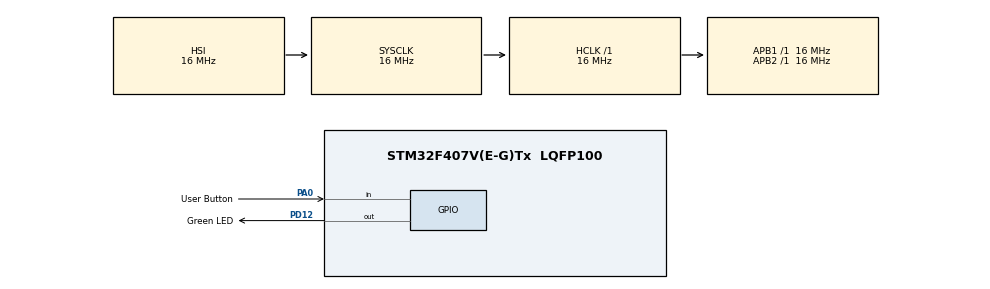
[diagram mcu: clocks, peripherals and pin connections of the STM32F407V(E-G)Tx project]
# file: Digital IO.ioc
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Mcu.Family=STM32F4
Mcu.Name=STM32F407V(E-G)Tx
Mcu.Package=LQFP100
NVIC.PriorityGroup=NVIC_PRIORITYGROUP_4
PA0-WKUP.GPIO_Label=User Button
PA0-WKUP.Signal=GPIO_Input
PA13.Mode=Trace_Asynchronous_SW
PA13.Signal=SYS_JTMS-SWDIO
PA14.Mode=Trace_Asynchronous_SW
PA14.Signal=SYS_JTCK-SWCLK
PB3.Mode=Trace_Asynchronous_SW
PB3.Signal=SYS_JTDO-SWO
PD12.GPIO_Label=Green LED
PD12.PinState=GPIO_PIN_RESET
PD12.Signal=GPIO_Output
ProjectManager.HeapSize=0x200
ProjectManager.StackSize=0x400
ProjectManager.TargetToolchain=STM32CubeIDE
RCC.AHBFreq_Value=16000000
RCC.APB1Freq_Value=16000000
RCC.APB2Freq_Value=16000000
RCC.CortexFreq_Value=16000000
RCC.HSE_VALUE=25000000
RCC.HSI_VALUE=16000000
RCC.LSE_VALUE=32768
RCC.SYSCLKFreq_VALUE=16000000
RCC.VCOOutputFreq_Value=192000000
board=custom

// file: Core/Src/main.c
/* USER CODE BEGIN Header */
/**
  ******************************************************************************
  * @file           : main.c
  * @brief          : Main program body
  ******************************************************************************
  * @attention
  *
  * Copyright (c) 2023 STMicroelectronics.
  * All rights reserved.
  *
  * This software is licensed under terms that can be found in the LICENSE file
  * in the root directory of this software component.
  * If no LICENSE file comes with this software, it is provided AS-IS.
  *
  ******************************************************************************
  */
/* USER CODE END Header */
#include "main.h"

/* USER CODE BEGIN Includes */
#include "stdio.h"

/* USER CODE END Includes */

void SystemClock_Config(void);
static void MX_GPIO_Init(void);
void blink(GPIO_PIN_Letter, GPIO_PIN_Number);
/* USER CODE BEGIN PFP */

// https://www.youtube.com/watch?v=FDCI4yfovfw
// ^ For printing using semihosting

// Docmentation at
// https://community.st.com/t5/stm32-mcus/how-to-use-semihosting-with-stm32cubeide-and-stm32/ta-p/49742

extern void initialise_monitor_handles(void);
/* USER CODE END PFP */

int main(void)
{
  /* USER CODE BEGIN 1 */
int bool = 0;
  /* USER CODE END 1 */

  /* MCU Configuration--------------------------------------------------------*/

  /* Reset of all peripherals, Initializes the Flash interface and the Systick. */
  HAL_Init();

  /* USER CODE BEGIN Init */
  initialise_monitor_handles();
  /* USER CODE END Init */

  /* Configure the system clock */
  SystemClock_Config();

  /* Initialize all configured peripherals */
  MX_GPIO_Init();
  /* USER CODE BEGIN 2 */
  printf("Hello World!\n");
  /* USER CODE END 2 */

  /* Infinite loop */
  /* USER CODE BEGIN WHILE */
  while (1)
  {
	  if(HAL_GPIO_ReadPin(GPIOA, GPIO_PIN_0))
		  bool = 1;

	  if((!HAL_GPIO_ReadPin(GPIOA, GPIO_PIN_0)) && bool){
		  blink(GPIOD, GPIO_PIN_12);
		  bool = 0;
		  printf("Hello World!\n");
	  }

    /* USER CODE END WHILE */

  }
}

void SystemClock_Config(void)
{
  RCC_OscInitTypeDef RCC_OscInitStruct = {0};
  RCC_ClkInitTypeDef RCC_ClkInitStruct = {0};

  /** Configure the main internal regulator output voltage
  */
  __HAL_RCC_PWR_CLK_ENABLE();
  __HAL_PWR_VOLTAGESCALING_CONFIG(PWR_REGULATOR_VOLTAGE_SCALE1);

  /** Initializes the RCC Oscillators according to the specified parameters
  * in the RCC_OscInitTypeDef structure.
  */
  RCC_OscInitStruct.OscillatorType = RCC_OSCILLATORTYPE_HSI;
  RCC_OscInitStruct.HSIState = RCC_HSI_ON;
  RCC_OscInitStruct.HSICalibrationValue = RCC_HSICALIBRATION_DEFAULT;
  RCC_OscInitStruct.PLL.PLLState = RCC_PLL_NONE;
  if (HAL_RCC_OscConfig(&RCC_OscInitStruct) != HAL_OK)
  {
    Error_Handler();
  }

  /** Initializes the CPU, AHB and APB buses clocks
  */
  RCC_ClkInitStruct.ClockType = RCC_CLOCKTYPE_HCLK|RCC_CLOCKTYPE_SYSCLK
                              |RCC_CLOCKTYPE_PCLK1|RCC_CLOCKTYPE_PCLK2;
  RCC_ClkInitStruct.SYSCLKSource = RCC_SYSCLKSOURCE_HSI;
  RCC_ClkInitStruct.AHBCLKDivider = RCC_SYSCLK_DIV1;
  RCC_ClkInitStruct.APB1CLKDivider = RCC_HCLK_DIV1;
  RCC_ClkInitStruct.APB2CLKDivider = RCC_HCLK_DIV1;

  if (HAL_RCC_ClockConfig(&RCC_ClkInitStruct, FLASH_LATENCY_0) != HAL_OK)
  {
    Error_Handler();
  }
}

static void MX_GPIO_Init(void)
{
  GPIO_InitTypeDef GPIO_InitStruct = {0};

  /* GPIO Ports Clock Enable */
  __HAL_RCC_GPIOA_CLK_ENABLE();
  __HAL_RCC_GPIOD_CLK_ENABLE();
  __HAL_RCC_GPIOB_CLK_ENABLE();

  /*Configure GPIO pin Output Level */
  HAL_GPIO_WritePin(Green_LED_GPIO_Port, Green_LED_Pin, GPIO_PIN_RESET);

  /*Configure GPIO pin : User_Button_Pin */
  GPIO_InitStruct.Pin = User_Button_Pin;
  GPIO_InitStruct.Mode = GPIO_MODE_INPUT;
  GPIO_InitStruct.Pull = GPIO_NOPULL;
  HAL_GPIO_Init(User_Button_GPIO_Port, &GPIO_InitStruct);

  /*Configure GPIO pin : Green_LED_Pin */
  GPIO_InitStruct.Pin = Green_LED_Pin;
  GPIO_InitStruct.Mode = GPIO_MODE_OUTPUT_PP;
  GPIO_InitStruct.Pull = GPIO_NOPULL;
  GPIO_InitStruct.Speed = GPIO_SPEED_FREQ_LOW;
  HAL_GPIO_Init(Green_LED_GPIO_Port, &GPIO_InitStruct);

}

void Error_Handler(void)
{
  __disable_irq();
  while (1)
  {
  }
}
